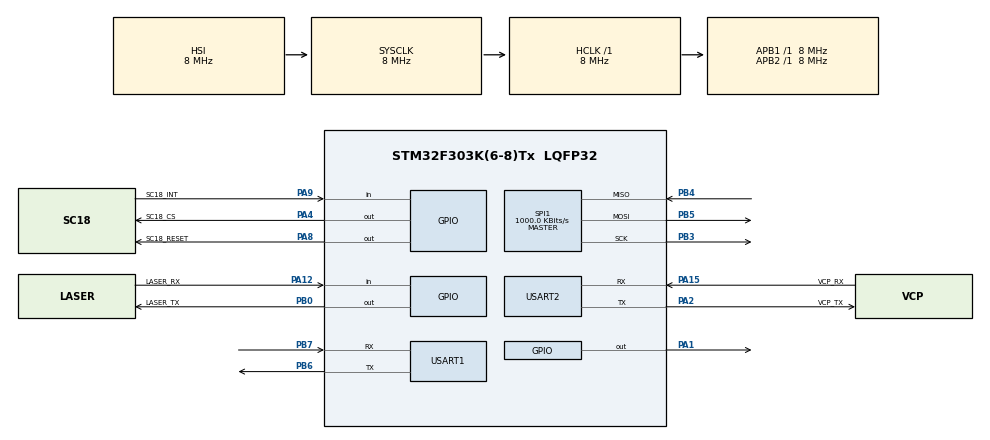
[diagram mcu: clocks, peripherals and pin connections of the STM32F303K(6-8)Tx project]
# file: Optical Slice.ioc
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Dma.Request0=USART1_RX
Dma.USART1_RX.0.Direction=DMA_PERIPH_TO_MEMORY
Dma.USART1_RX.0.Instance=DMA1_Channel5
Dma.USART1_RX.0.MemDataAlignment=DMA_MDATAALIGN_BYTE
Dma.USART1_RX.0.MemInc=DMA_MINC_ENABLE
Dma.USART1_RX.0.Mode=DMA_NORMAL
Dma.USART1_RX.0.PeriphDataAlignment=DMA_PDATAALIGN_BYTE
Dma.USART1_RX.0.PeriphInc=DMA_PINC_DISABLE
Dma.USART1_RX.0.Priority=DMA_PRIORITY_LOW
Mcu.Family=STM32F3
Mcu.Name=STM32F303K(6-8)Tx
Mcu.Package=LQFP32
NVIC.DMA1_Channel5_IRQn=true\:0\:0\:false\:false\:true\:false\:true\:true
NVIC.PriorityGroup=NVIC_PRIORITYGROUP_4
PA1.Signal=GPIO_Output
PA12.GPIO_Label=LASER_RX
PA12.GPIO_PuPd=GPIO_PULLUP
PA12.Signal=GPIO_Input
PA13.GPIO_Label=SWDIO
PA13.Mode=Serial_Wire
PA13.Signal=SYS_JTMS-SWDIO
PA14.GPIO_Label=SWCLK
PA14.Mode=Serial_Wire
PA14.Signal=SYS_JTCK-SWCLK
PA15.GPIO_Label=VCP_RX
PA15.Mode=Asynchronous
PA15.Signal=USART2_RX
PA2.GPIO_Label=VCP_TX
PA2.Mode=Asynchronous
PA2.Signal=USART2_TX
PA4.GPIO_Label=SC18_CS
PA4.GPIO_Speed=GPIO_SPEED_FREQ_HIGH
PA4.Signal=GPIO_Output
PA8.GPIO_Label=SC18_RESET
PA8.Signal=GPIO_Output
PA9.GPIO_Label=SC18_INT
PA9.Signal=GPIO_Input
PB0.GPIO_Label=LASER_TX
PB0.Signal=GPIO_Output
PB3.Mode=Full_Duplex_Master
PB3.Signal=SPI1_SCK
PB4.Mode=Full_Duplex_Master
PB4.Signal=SPI1_MISO
PB5.Mode=Full_Duplex_Master
PB5.Signal=SPI1_MOSI
PB6.Mode=Asynchronous
PB6.Signal=USART1_TX
PB7.Mode=Asynchronous
PB7.Signal=USART1_RX
PF0\ /\ OSC_IN.GPIO_Label=MCO
PF0\ /\ OSC_IN.Mode=HSE-External-Clock-Source
PF0\ /\ OSC_IN.Signal=RCC_OSC_IN
ProjectManager.HeapSize=0x200
ProjectManager.StackSize=0x400
ProjectManager.TargetToolchain=STM32CubeIDE
RCC.AHBFreq_Value=8000000
RCC.APB1Freq_Value=8000000
RCC.APB2Freq_Value=8000000
RCC.CortexFreq_Value=8000000
RCC.HSE_VALUE=8000000
RCC.HSI_VALUE=8000000
RCC.SYSCLKFreq_VALUE=8000000
SPI1.BaudRatePrescaler=SPI_BAUDRATEPRESCALER_8
SPI1.CLKPhase=SPI_PHASE_2EDGE
SPI1.CLKPolarity=SPI_POLARITY_HIGH
SPI1.CalculateBaudRate=1000.0 KBits/s
SPI1.DataSize=SPI_DATASIZE_8BIT
SPI1.Direction=SPI_DIRECTION_2LINES
SPI1.Mode=SPI_MODE_MASTER
SPI1.VirtualType=VM_MASTER
USART1.VirtualMode-Asynchronous=VM_ASYNC
USART2.VirtualMode-Asynchronous=VM_ASYNC
board=NUCLEO-F303K8

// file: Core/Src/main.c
/* USER CODE BEGIN Header */
/**
  ******************************************************************************
  * @file           : main.c
  * @brief          : Main program body
  ******************************************************************************
  * @attention
  *
  * Copyright (c) 2026 STMicroelectronics.
  * All rights reserved.
  *
  * This software is licensed under terms that can be found in the LICENSE file
  * in the root directory of this software component.
  * If no LICENSE file comes with this software, it is provided AS-IS.
  *
  ******************************************************************************
  */
/* USER CODE END Header */
#include "main.h"
#include "dma.h"
#include "spi.h"
#include "usart.h"
#include "gpio.h"

/* USER CODE BEGIN Includes */
#include "optical_slice_app.h"

/* USER CODE END Includes */

void SystemClock_Config(void);

int main(void)
{

  /* MCU Configuration--------------------------------------------------------*/

  /* Reset of all peripherals, Initializes the Flash interface and the Systick. */
  HAL_Init();

  /* Configure the system clock */
  SystemClock_Config();

  /* Initialize all configured peripherals */
  MX_GPIO_Init();
  MX_DMA_Init();
  MX_USART2_UART_Init();
  MX_SPI1_Init();
  MX_USART1_UART_Init();
  /* USER CODE BEGIN 2 */

  OpticalSlice_Init();

  /* USER CODE END 2 */

  /* Infinite loop */
  while (1)
  {

    /* USER CODE BEGIN 3 */
    OpticalSlice_Run();
  }
  /* USER CODE END 3 */
}

void SystemClock_Config(void)
{
  RCC_OscInitTypeDef RCC_OscInitStruct = {0};
  RCC_ClkInitTypeDef RCC_ClkInitStruct = {0};
  RCC_PeriphCLKInitTypeDef PeriphClkInit = {0};

  /** Initializes the RCC Oscillators according to the specified parameters
  * in the RCC_OscInitTypeDef structure.
  */
  RCC_OscInitStruct.OscillatorType = RCC_OSCILLATORTYPE_HSI;
  RCC_OscInitStruct.HSIState = RCC_HSI_ON;
  RCC_OscInitStruct.HSICalibrationValue = RCC_HSICALIBRATION_DEFAULT;
  RCC_OscInitStruct.PLL.PLLState = RCC_PLL_NONE;
  if (HAL_RCC_OscConfig(&RCC_OscInitStruct) != HAL_OK)
  {
    Error_Handler();
  }

  /** Initializes the CPU, AHB and APB buses clocks
  */
  RCC_ClkInitStruct.ClockType = RCC_CLOCKTYPE_HCLK|RCC_CLOCKTYPE_SYSCLK
                              |RCC_CLOCKTYPE_PCLK1|RCC_CLOCKTYPE_PCLK2;
  RCC_ClkInitStruct.SYSCLKSource = RCC_SYSCLKSOURCE_HSI;
  RCC_ClkInitStruct.AHBCLKDivider = RCC_SYSCLK_DIV1;
  RCC_ClkInitStruct.APB1CLKDivider = RCC_HCLK_DIV1;
  RCC_ClkInitStruct.APB2CLKDivider = RCC_HCLK_DIV1;

  if (HAL_RCC_ClockConfig(&RCC_ClkInitStruct, FLASH_LATENCY_0) != HAL_OK)
  {
    Error_Handler();
  }
  PeriphClkInit.PeriphClockSelection = RCC_PERIPHCLK_USART1;
  PeriphClkInit.Usart1ClockSelection = RCC_USART1CLKSOURCE_PCLK1;
  if (HAL_RCCEx_PeriphCLKConfig(&PeriphClkInit) != HAL_OK)
  {
    Error_Handler();
  }
}

void Error_Handler(void)
{
  __disable_irq();
  while (1)
  {
  }
}
